# EFM32JG1B200F128GM32 register map
File version: 4.2.0
Registers are 32-bit, read-write, reset 0x0 unless marked. A register's access mark holds for its fields unless they carry their own. Offsets are from the block's base; [hi:lo] are bit positions; {n}, {i} and the like mark numbered series; 'fields as' and 'values as' point back to an identical list.

## CMU
Base 0x400E4000
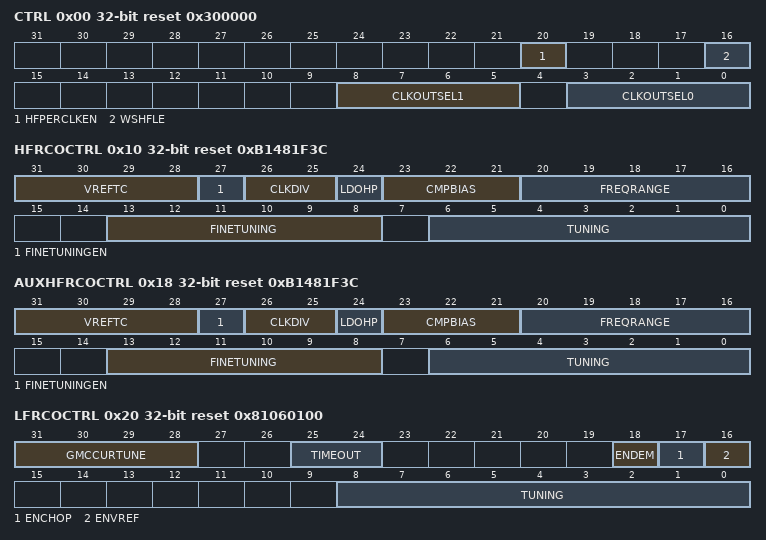
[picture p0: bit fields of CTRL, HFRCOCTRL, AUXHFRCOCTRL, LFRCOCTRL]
0x00 CTRL reset 0x300000 — CMU Control Register
  [20] HFPERCLKEN — HFPERCLK Enable
  [16] WSHFLE — Wait State for High-Frequency LE Interface
  [8:5] CLKOUTSEL1 — Clock Output Select 1
    0=DISABLED; 1=ULFRCO (ULFRCO (directly from oscillator)); 2=LFRCO (LFRCO (directly from oscillator)); 3=LFXO (LFXO (directly from oscillator)); 6=HFXO (HFXO (directly from oscillator)); 7=HFEXPCLK; 9=ULFRCOQ (ULFRCO (qualified)); 10=LFRCOQ (LFRCO (qualified)); 11=LFXOQ (LFXO (qualified)); 12=HFRCOQ (HFRCO (qualified)); 13=AUXHFRCOQ (AUXHFRCO (qualified)); 14=HFXOQ (HFXO (qualified)); 15=HFSRCCLK
  [3:0] CLKOUTSEL0 — Clock Output Select 0
    values as CLKOUTSEL1
0x10 HFRCOCTRL reset 0xB1481F3C — HFRCO Control Register
  [31:28] VREFTC — HFRCO Temperature Coefficient Trim on Comparator Reference
  [27] FINETUNINGEN — Enable reference for fine tuning
  [26:25] CLKDIV — Locally divide HFRCO Clock Output
    0=DIV1 (Divide by 1.); 1=DIV2 (Divide by 2.); 2=DIV4 (Divide by 4.)
  [24] LDOHP — HFRCO LDO High Power Mode
  [23:21] CMPBIAS — HFRCO Comparator Bias Current
  [20:16] FREQRANGE — HFRCO Frequency Range
  [13:8] FINETUNING — HFRCO Fine Tuning Value
  [6:0] TUNING — HFRCO Tuning Value
0x18 AUXHFRCOCTRL reset 0xB1481F3C — AUXHFRCO Control Register
  [31:28] VREFTC — AUXHFRCO Temperature Coefficient Trim on Comparator Reference
  [27] FINETUNINGEN — Enable reference for fine tuning
  [26:25] CLKDIV — Locally divide AUXHFRCO Clock Output
    values as HFRCOCTRL.CLKDIV
  [24] LDOHP — AUXHFRCO LDO High Power Mode
  [23:21] CMPBIAS — AUXHFRCO Comparator Bias Current
  [20:16] FREQRANGE — AUXHFRCO Frequency Range
  [13:8] FINETUNING — AUXHFRCO Fine Tuning Value
  [6:0] TUNING — AUXHFRCO Tuning Value
0x20 LFRCOCTRL reset 0x81060100 — LFRCO Control Register
  [31:28] GMCCURTUNE — Tuning of gmc current
  [25:24] TIMEOUT — LFRCO Timeout
    0=2CYCLES (Timeout period of 2 cycles); 1=16CYCLES (Timeout period of 16 cycles); 2=32CYCLES (Timeout period of 32 cycles)
  [18] ENDEM — Enable dynamic element matching
  [17] ENCHOP — Enable comparator chopping
  [16] ENVREF — Enable duty cycling of vref
  [8:0] TUNING — LFRCO Tuning Value
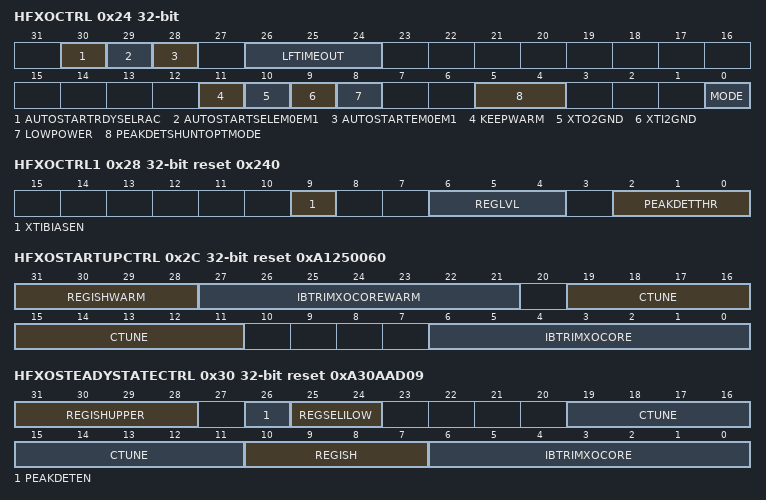
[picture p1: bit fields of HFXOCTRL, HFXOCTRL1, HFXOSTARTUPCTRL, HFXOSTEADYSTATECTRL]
0x24 HFXOCTRL — HFXO Control Register
  [30] AUTOSTARTRDYSELRAC — Automatically start HFXO on RAC wake-up and select it upon HFXO Ready
  [29] AUTOSTARTSELEM0EM1 — Automatically start and select of HFXO upon EM0/EM1 entry from EM2/EM3
  [28] AUTOSTARTEM0EM1 — Automatically start of HFXO upon EM0/EM1 entry from EM2/EM3
  [26:24] LFTIMEOUT — HFXO Low Frequency Timeout
    0=0CYCLES (Timeout period of 0 cycles (disabled)); 1=2CYCLES (Timeout period of 2 cycles); 2=4CYCLES (Timeout period of 4 cycles); 3=16CYCLES (Timeout period of 16 cycles); 4=32CYCLES (Timeout period of 32 cycles); 5=64CYCLES (Timeout period of 64 cycles); 6=1KCYCLES (Timeout period of 1024 cycles); 7=4KCYCLES (Timeout period of 4096 cycles)
  [11] KEEPWARM — Keep HFXO warm when turning off HFXO.
  [10] XTO2GND — Clamp HFXTAL_P pin to ground when HFXO oscillator is off and KEEPWARM=0.
  [9] XTI2GND — Clamp HFXTAL_N pin to ground when HFXO oscillator is off and KEEPWARM=0.
  [8] LOWPOWER — Low power mode control. PSR performance is reduced to enable low current consumption.
  [5:4] PEAKDETSHUNTOPTMODE — HFXO Automatic Peak Detection and shunt current optimization mode
    0=AUTOCMD (Automatic control of HFXO peak detection and shunt optimization sequences. CMU_CMD HFXOPEAKDETSTART and HFXOSHUNTOPTSTART can also be used.); 1=CMD (CMU_CMD HFXOPEAKDETSTART and HFXOSHUNTOPTSTART can be used to trigger peak detection and shunt optimization sequences.); 2=MANUAL (CMU_HFXOSTEADYSTATECTRL IBTRIMXOCORE, REGISH, REGSELILOW, and PEAKDETEN are under full software control and are allowed to be changed once HFXO is ready.)
  [0] MODE — HFXO Mode
0x28 HFXOCTRL1 reset 0x240 — HFXO Control 1
  [9] XTIBIASEN — Reserved for internal use. Do not change.
  [6:4] REGLVL — Reserved for internal use. Do not change.
  [2:0] PEAKDETTHR — Sets the Peak Detector amplitude detection threshold levels
0x2C HFXOSTARTUPCTRL reset 0xA1250060 — HFXO Startup Control
  [31:28] REGISHWARM — Sets the regulator output current level (shunt regulator). Ish = 120uA + REGISHWARM x 120uA
  [27:21] IBTRIMXOCOREWARM — Sets the oscillator core bias current. Current (uA) = IBTRIMXOCOREWARM x 40uA. Bits 6 and 5 may only be high in the crystal oscillator startup phase
  [19:11] CTUNE — Sets oscillator tuning capacitance. Capacitance on HFXTAL_N and HFXTAL_P (pF) = Ctune = Cpar + CTUNE<8:0> x 40fF. Max Ctune 25pF (CLmax ~12.5pF). CL(DNLmax)=50fF ~ 0.6ppm (12.5ppm/pF)
  [6:0] IBTRIMXOCORE — Sets the startup oscillator core bias current. Current (uA) = IBTRIMXOCORE x 40uA. Bits 6 and 5 may only be high in the crystal oscillator startup phase
0x30 HFXOSTEADYSTATECTRL reset 0xA30AAD09 — HFXO Steady State control
  [31:28] REGISHUPPER — Set regulator output current level (shunt regulator). Ish = 120uA + REGISHUPPER x 120uA
  [26] PEAKDETEN — Enables oscillator peak detectors
  [25:24] REGSELILOW — Controls regulator minimum shunt current detection relative to nominal
  [19:11] CTUNE — Sets oscillator tuning capacitance. Capacitance on HFXTAL_N and HFXTAL_P (pF) = Ctune = Cpar + CTUNE<8:0> x 40fF. Max Ctune 25pF (CLmax ~12.5pF). CL(DNLmax)=50fF ~ 0.6ppm (12.5ppm/pF)
  [10:7] REGISH — Sets the steady state regulator output current level (shunt regulator). Ish = 120uA + REGISH x 120uA
  [6:0] IBTRIMXOCORE — Sets the steady state oscillator core bias current. Current (uA) = IBTRIMXOCORE x 40uA. Bits 6 and 5 may only be high in the crystal oscillator startup phase
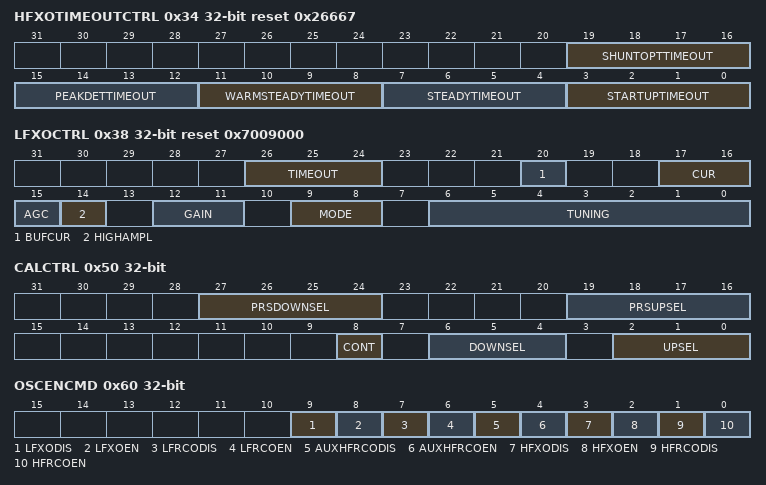
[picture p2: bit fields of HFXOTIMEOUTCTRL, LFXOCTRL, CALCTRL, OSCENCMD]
0x34 HFXOTIMEOUTCTRL reset 0x26667 — HFXO Timeout Control
  [all] fields
    0=2CYCLES (Timeout period of 2 cycles); 1=4CYCLES (Timeout period of 4 cycles); 2=16CYCLES (Timeout period of 16 cycles); 3=32CYCLES (Timeout period of 32 cycles); 4=256CYCLES (Timeout period of 256 cycles); 5=1KCYCLES (Timeout period of 1024 cycles); 6=2KCYCLES (Timeout period of 2048 cycles); 7=4KCYCLES (Timeout period of 4096 cycles); 8=8KCYCLES (Timeout period of 8192 cycles); 9=16KCYCLES (Timeout period of 16384 cycles); 10=32KCYCLES (Timeout period of 32768 cycles)
  [19:16] SHUNTOPTTIMEOUT — Wait duration in HFXO shunt current optimization wait state
  [15:12] PEAKDETTIMEOUT — Wait duration in HFXO peak detection wait state
  [11:8] WARMSTEADYTIMEOUT — Wait duration in HFXO warm startup steady wait state
  [7:4] STEADYTIMEOUT — Wait duration in HFXO startup steady wait state
  [3:0] STARTUPTIMEOUT — Wait duration in HFXO startup enable wait state
0x38 LFXOCTRL reset 0x7009000 — LFXO Control Register
  [26:24] TIMEOUT — LFXO Timeout
    0=2CYCLES (Timeout period of 2 cycles); 1=256CYCLES (Timeout period of 256 cycles); 2=1KCYCLES (Timeout period of 1024 cycles); 3=2KCYCLES (Timeout period of 2048 cycles); 4=4KCYCLES (Timeout period of 4096 cycles); 5=8KCYCLES (Timeout period of 8192 cycles); 6=16KCYCLES (Timeout period of 16384 cycles); 7=32KCYCLES (Timeout period of 32768 cycles)
  [20] BUFCUR — LFXO Buffer Bias Current
  [17:16] CUR — LFXO Current Trim
  [15] AGC — LFXO AGC Enable
  [14] HIGHAMPL — LFXO High XTAL Oscillation Amplitude Enable
  [12:11] GAIN — LFXO Startup Gain
  [9:8] MODE — LFXO Mode
    0=XTAL (32768 Hz crystal oscillator); 1=BUFEXTCLK (An AC coupled buffer is coupled in series with LFXTAL_N pin, suitable for external sinus wave (32768 Hz).); 2=DIGEXTCLK (Digital external clock on LFXTAL_N pin. Oscillator is effectively bypassed.)
  [6:0] TUNING — LFXO Internal Capacitor Array Tuning Value
0x50 CALCTRL — Calibration Control Register
  [27:24] PRSDOWNSEL — PRS Select for PRS Input when selected in DOWNSEL
    {v}=PRSCH{v} (PRS Channel {v} selected as input) (v=0..11)
  [19:16] PRSUPSEL — PRS Select for PRS Input when selected in UPSEL
    {v}=PRSCH{v} (PRS Channel {v} selected as input) (v=0..11)
  [8] CONT — Continuous Calibration
  [6:4] DOWNSEL — Calibration Down-counter Select
    0=HFCLK (Select HFCLK for down-counter); 1=HFXO (Select HFXO for down-counter); 2=LFXO (Select LFXO for down-counter); 3=HFRCO (Select HFRCO for down-counter); 4=LFRCO (Select LFRCO for down-counter); 5=AUXHFRCO (Select AUXHFRCO for down-counter); 6=PRS (Select PRS input selected by PRSDOWNSEL as down-counter)
  [2:0] UPSEL — Calibration Up-counter Select
    0=HFXO (Select HFXO as up-counter); 1=LFXO (Select LFXO as up-counter); 2=HFRCO (Select HFRCO as up-counter); 3=LFRCO (Select LFRCO as up-counter); 4=AUXHFRCO (Select AUXHFRCO as up-counter); 5=PRS (Select PRS input selected by PRSUPSEL as up-counter)
0x54 CALCNT — Calibration Counter Register
  [19:0] CALCNT — Calibration Counter
0x60 OSCENCMD wo — Oscillator Enable/Disable Command Register
  [9] LFXODIS — LFXO Disable
  [8] LFXOEN — LFXO Enable
  [7] LFRCODIS — LFRCO Disable
  [6] LFRCOEN — LFRCO Enable
  [5] AUXHFRCODIS — AUXHFRCO Disable
  [4] AUXHFRCOEN — AUXHFRCO Enable
  [3] HFXODIS — HFXO Disable
  [2] HFXOEN — HFXO Enable
  [1] HFRCODIS — HFRCO Disable
  [0] HFRCOEN — HFRCO Enable
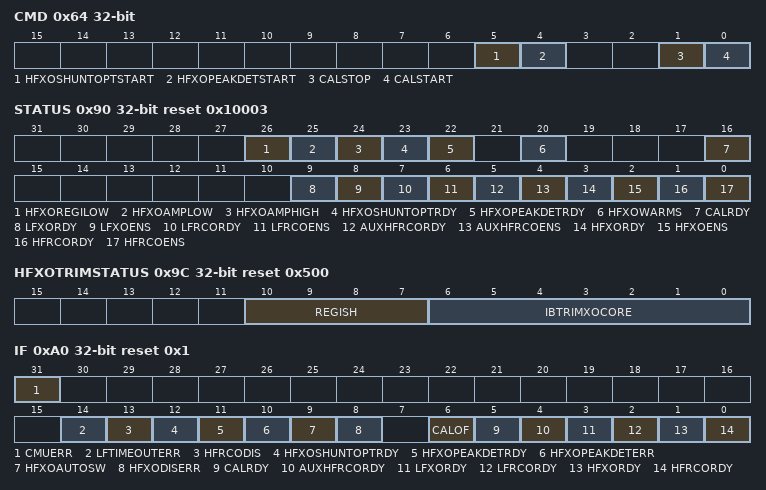
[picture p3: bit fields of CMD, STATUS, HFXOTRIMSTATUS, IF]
0x64 CMD wo — Command Register
  [5] HFXOSHUNTOPTSTART — HFXO Shunt Current Optimization Start
  [4] HFXOPEAKDETSTART — HFXO Peak Detection Start
  [1] CALSTOP — Calibration Stop
  [0] CALSTART — Calibration Start
0x70 DBGCLKSEL — Debug Trace Clock Select
  [0] DBG — Debug Trace Clock
    0=AUXHFRCO (AUXHFRCO is the debug trace clock); 1=HFCLK (HFCLK is the debug trace clock)
0x74 HFCLKSEL wo — High Frequency Clock Select Command Register
  [2:0] HF — HFCLK Select
    1=HFRCO (Select HFRCO as HFCLK); 2=HFXO (Select HFXO as HFCLK); 3=LFRCO (Select LFRCO as HFCLK); 4=LFXO (Select LFXO as HFCLK)
0x80 LFACLKSEL — Low Frequency A Clock Select Register
  [2:0] LFA — Clock Select for LFA
    0=DISABLED (LFACLK is disabled); 1=LFRCO (LFRCO selected as LFACLK); 2=LFXO (LFXO selected as LFACLK); 4=ULFRCO (ULFRCO selected as LFACLK)
0x84 LFBCLKSEL — Low Frequency B Clock Select Register
  [2:0] LFB — Clock Select for LFB
    0=DISABLED (LFBCLK is disabled); 1=LFRCO (LFRCO selected as LFBCLK); 2=LFXO (LFXO selected as LFBCLK); 3=HFCLKLE (HFCLK divided by two/four is selected as LFBCLK); 4=ULFRCO (ULFRCO selected as LFBCLK)
0x88 LFECLKSEL — Low Frequency E Clock Select Register
  [2:0] LFE — Clock Select for LFE
    0=DISABLED (LFECLK is disabled); 1=LFRCO (LFRCO selected as LFECLK); 2=LFXO (LFXO selected as LFECLK); 4=ULFRCO (ULFRCO selected as LFECLK)
0x90 STATUS ro reset 0x10003
  [26] HFXOREGILOW — HFXO regulator shunt current too low
  [25] HFXOAMPLOW — HFXO amplitude tuning value too low
  [24] HFXOAMPHIGH — HFXO oscillation amplitude is too high
  [23] HFXOSHUNTOPTRDY — HFXO Shunt Current Optimization ready
  [22] HFXOPEAKDETRDY — HFXO Peak Detection Ready
  [20] HFXOWARMS — HFXO Warm Status
  [16] CALRDY — Calibration Ready
  [9] LFXORDY — LFXO Ready
  [8] LFXOENS — LFXO Enable Status
  [7] LFRCORDY — LFRCO Ready
  [6] LFRCOENS — LFRCO Enable Status
  [5] AUXHFRCORDY — AUXHFRCO Ready
  [4] AUXHFRCOENS — AUXHFRCO Enable Status
  [3] HFXORDY — HFXO Ready
  [2] HFXOENS — HFXO Enable Status
  [1] HFRCORDY — HFRCO Ready
  [0] HFRCOENS — HFRCO Enable Status
0x94 HFCLKSTATUS ro reset 0x1
  [2:0] SELECTED — HFCLK Selected
    1=HFRCO (HFRCO is selected as HFCLK clock source); 2=HFXO (HFXO is selected as HFCLK clock source); 3=LFRCO (LFRCO is selected as HFCLK clock source); 4=LFXO (LFXO is selected as HFCLK clock source)
0x9C HFXOTRIMSTATUS ro reset 0x500
  [10:7] REGISH — Value of REGISH found by automatic HFXO shunt current optimization algorithm. Can be used as initial value for REGISH value in the CMU_HFXOSTEADYSTATECTRL register if HFXO is to be started again.
  [6:0] IBTRIMXOCORE — Value of IBTRIMXOCORE found by automatic HFXO peak detection algorithm. Can be used as initial value for IBTRIMXOCORE in the CMU_HFXOSTEADYSTATECTRL register if HFXO is to be started again.
0xA0 IF ro reset 0x1 — Interrupt Flag Register
  [31] CMUERR — CMU Error Interrupt Flag
  [14] LFTIMEOUTERR — Low Frequency Timeout Error Interrupt Flag
  [13] HFRCODIS — HFRCO Disable Interrupt Flag
  [12] HFXOSHUNTOPTRDY — HFXO Automatic Shunt Current Optimization Ready Interrupt Flag
  [11] HFXOPEAKDETRDY — HFXO Automatic Peak Detection Ready Interrupt Flag
  [10] HFXOPEAKDETERR — HFXO Automatic Peak Detection Error Interrupt Flag
  [9] HFXOAUTOSW — HFXO Automatic Switch Interrupt Flag
  [8] HFXODISERR — HFXO Disable Error Interrupt Flag
  [6] CALOF — Calibration Overflow Interrupt Flag
  [5] CALRDY — Calibration Ready Interrupt Flag
  [4] AUXHFRCORDY — AUXHFRCO Ready Interrupt Flag
  [3] LFXORDY — LFXO Ready Interrupt Flag
  [2] LFRCORDY — LFRCO Ready Interrupt Flag
  [1] HFXORDY — HFXO Ready Interrupt Flag
  [0] HFRCORDY — HFRCO Ready Interrupt Flag
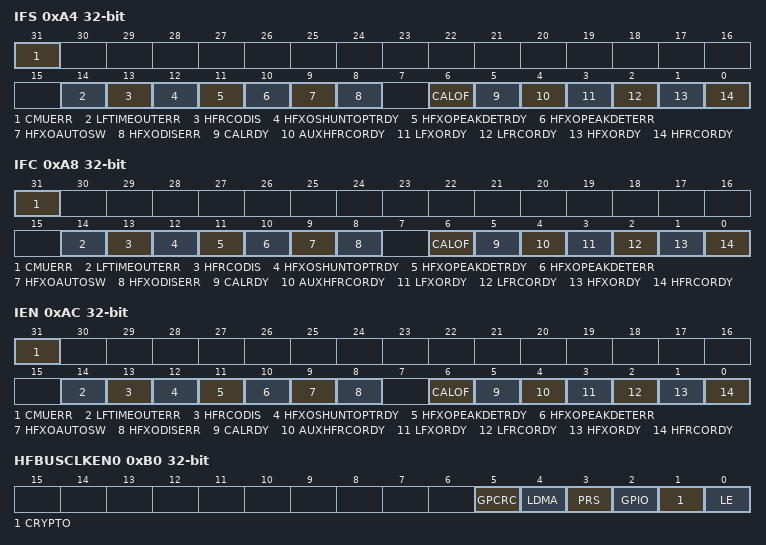
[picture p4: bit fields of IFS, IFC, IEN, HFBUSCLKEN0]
0xA4 IFS wo — Interrupt Flag Set Register
  [31] CMUERR — Set CMUERR Interrupt Flag
  [14] LFTIMEOUTERR — Set LFTIMEOUTERR Interrupt Flag
  [13] HFRCODIS — Set HFRCODIS Interrupt Flag
  [12] HFXOSHUNTOPTRDY — Set HFXOSHUNTOPTRDY Interrupt Flag
  [11] HFXOPEAKDETRDY — Set HFXOPEAKDETRDY Interrupt Flag
  [10] HFXOPEAKDETERR — Set HFXOPEAKDETERR Interrupt Flag
  [9] HFXOAUTOSW — Set HFXOAUTOSW Interrupt Flag
  [8] HFXODISERR — Set HFXODISERR Interrupt Flag
  [6] CALOF — Set CALOF Interrupt Flag
  [5] CALRDY — Set CALRDY Interrupt Flag
  [4] AUXHFRCORDY — Set AUXHFRCORDY Interrupt Flag
  [3] LFXORDY — Set LFXORDY Interrupt Flag
  [2] LFRCORDY — Set LFRCORDY Interrupt Flag
  [1] HFXORDY — Set HFXORDY Interrupt Flag
  [0] HFRCORDY — Set HFRCORDY Interrupt Flag
0xA8 IFC wo — Interrupt Flag Clear Register
  [31] CMUERR — Clear CMUERR Interrupt Flag
  [14] LFTIMEOUTERR — Clear LFTIMEOUTERR Interrupt Flag
  [13] HFRCODIS — Clear HFRCODIS Interrupt Flag
  [12] HFXOSHUNTOPTRDY — Clear HFXOSHUNTOPTRDY Interrupt Flag
  [11] HFXOPEAKDETRDY — Clear HFXOPEAKDETRDY Interrupt Flag
  [10] HFXOPEAKDETERR — Clear HFXOPEAKDETERR Interrupt Flag
  [9] HFXOAUTOSW — Clear HFXOAUTOSW Interrupt Flag
  [8] HFXODISERR — Clear HFXODISERR Interrupt Flag
  [6] CALOF — Clear CALOF Interrupt Flag
  [5] CALRDY — Clear CALRDY Interrupt Flag
  [4] AUXHFRCORDY — Clear AUXHFRCORDY Interrupt Flag
  [3] LFXORDY — Clear LFXORDY Interrupt Flag
  [2] LFRCORDY — Clear LFRCORDY Interrupt Flag
  [1] HFXORDY — Clear HFXORDY Interrupt Flag
  [0] HFRCORDY — Clear HFRCORDY Interrupt Flag
0xAC IEN — Interrupt Enable Register
  [31] CMUERR — CMUERR Interrupt Enable
  [14] LFTIMEOUTERR — LFTIMEOUTERR Interrupt Enable
  [13] HFRCODIS — HFRCODIS Interrupt Enable
  [12] HFXOSHUNTOPTRDY — HFXOSHUNTOPTRDY Interrupt Enable
  [11] HFXOPEAKDETRDY — HFXOPEAKDETRDY Interrupt Enable
  [10] HFXOPEAKDETERR — HFXOPEAKDETERR Interrupt Enable
  [9] HFXOAUTOSW — HFXOAUTOSW Interrupt Enable
  [8] HFXODISERR — HFXODISERR Interrupt Enable
  [6] CALOF — CALOF Interrupt Enable
  [5] CALRDY — CALRDY Interrupt Enable
  [4] AUXHFRCORDY — AUXHFRCORDY Interrupt Enable
  [3] LFXORDY — LFXORDY Interrupt Enable
  [2] LFRCORDY — LFRCORDY Interrupt Enable
  [1] HFXORDY — HFXORDY Interrupt Enable
  [0] HFRCORDY — HFRCORDY Interrupt Enable
0xB0 HFBUSCLKEN0 — High Frequency Bus Clock Enable Register 0
  [5] GPCRC — General Purpose CRC Clock Enable
  [4] LDMA — Linked Direct Memory Access Controller Clock Enable
  [3] PRS — Peripheral Reflex System Clock Enable
  [2] GPIO — General purpose Input/Output Clock Enable
  [1] CRYPTO — Advanced Encryption Standard Accelerator Clock Enable
  [0] LE — Low Energy Peripheral Interface Clock Enable
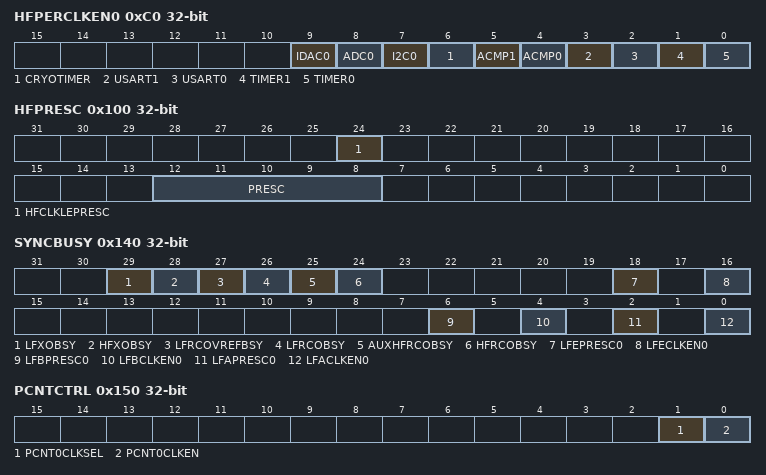
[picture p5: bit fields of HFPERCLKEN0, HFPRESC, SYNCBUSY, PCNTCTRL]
0xC0 HFPERCLKEN0 — High Frequency Peripheral Clock Enable Register 0
  [9] IDAC0 — Current Digital to Analog Converter 0 Clock Enable
  [8] ADC0 — Analog to Digital Converter 0 Clock Enable
  [7] I2C0 — I2C 0 Clock Enable
  [6] CRYOTIMER — CryoTimer Clock Enable
  [5] ACMP1 — Analog Comparator 1 Clock Enable
  [4] ACMP0 — Analog Comparator 0 Clock Enable
  [3] USART1 — Universal Synchronous/Asynchronous Receiver/Transmitter 1 Clock Enable
  [2] USART0 — Universal Synchronous/Asynchronous Receiver/Transmitter 0 Clock Enable
  [1] TIMER1 — Timer 1 Clock Enable
  [0] TIMER0 — Timer 0 Clock Enable
0xE0 LFACLKEN0 — Low Frequency A Clock Enable Register 0 (Async Reg)
  [0] LETIMER0 — Low Energy Timer 0 Clock Enable
0xE8 LFBCLKEN0 — Low Frequency B Clock Enable Register 0 (Async Reg)
  [0] LEUART0 — Low Energy UART 0 Clock Enable
0xF0 LFECLKEN0 — Low Frequency E Clock Enable Register 0 (Async Reg)
  [0] RTCC — Real-Time Counter and Calendar Clock Enable
0x100 HFPRESC — High Frequency Clock Prescaler Register
  [24] HFCLKLEPRESC — HFCLKLE prescaler
    0=DIV2 (HFCLKLE is HFBUSCLKLE divided by 2.); 1=DIV4 (HFCLKLE is HFBUSCLKLE divided by 4.)
  [12:8] PRESC — HFCLK Prescaler
    0=NODIVISION
0x108 HFCOREPRESC — High Frequency Core Clock Prescaler Register
  [16:8] PRESC — HFCORECLK Prescaler
    0=NODIVISION
0x10C HFPERPRESC — High Frequency Peripheral Clock Prescaler Register
  [16:8] PRESC — HFPERCLK Prescaler
    0=NODIVISION
0x114 HFEXPPRESC — High Frequency Export Clock Prescaler Register
  [12:8] PRESC — HFEXPCLK Prescaler
    0=NODIVISION
0x120 LFAPRESC0 — Low Frequency A Prescaler Register 0 (Async Reg)
  [3:0] LETIMER0 — Low Energy Timer 0 Prescaler
    0=DIV1 (LFACLKLETIMER0 = LFACLK); 1=DIV2 (LFACLKLETIMER0 = LFACLK/2); 2=DIV4 (LFACLKLETIMER0 = LFACLK/4); 3=DIV8 (LFACLKLETIMER0 = LFACLK/8); 4=DIV16 (LFACLKLETIMER0 = LFACLK/16); 5=DIV32 (LFACLKLETIMER0 = LFACLK/32); 6=DIV64 (LFACLKLETIMER0 = LFACLK/64); 7=DIV128 (LFACLKLETIMER0 = LFACLK/128); 8=DIV256 (LFACLKLETIMER0 = LFACLK/256); 9=DIV512 (LFACLKLETIMER0 = LFACLK/512); 10=DIV1024 (LFACLKLETIMER0 = LFACLK/1024); 11=DIV2048 (LFACLKLETIMER0 = LFACLK/2048); 12=DIV4096 (LFACLKLETIMER0 = LFACLK/4096); 13=DIV8192 (LFACLKLETIMER0 = LFACLK/8192); 14=DIV16384 (LFACLKLETIMER0 = LFACLK/16384); 15=DIV32768 (LFACLKLETIMER0 = LFACLK/32768)
0x128 LFBPRESC0 — Low Frequency B Prescaler Register 0 (Async Reg)
  [1:0] LEUART0 — Low Energy UART 0 Prescaler
    0=DIV1 (LFBCLKLEUART0 = LFBCLK); 1=DIV2 (LFBCLKLEUART0 = LFBCLK/2); 2=DIV4 (LFBCLKLEUART0 = LFBCLK/4); 3=DIV8 (LFBCLKLEUART0 = LFBCLK/8)
0x130 LFEPRESC0 — Low Frequency E Prescaler Register 0 (Async Reg)
  [3:0] RTCC ro — Real-Time Counter and Calendar Prescaler
    0=DIV1 (LFECLKRTCC = LFECLK)
0x140 SYNCBUSY ro — Synchronization Busy Register
  [29] LFXOBSY — LFXO Busy
  [28] HFXOBSY — HFXO Busy
  [27] LFRCOVREFBSY — LFRCO VREF Busy
  [26] LFRCOBSY — LFRCO Busy
  [25] AUXHFRCOBSY — AUXHFRCO Busy
  [24] HFRCOBSY — HFRCO Busy
  [18] LFEPRESC0 — Low Frequency E Prescaler 0 Busy
  [16] LFECLKEN0 — Low Frequency E Clock Enable 0 Busy
  [6] LFBPRESC0 — Low Frequency B Prescaler 0 Busy
  [4] LFBCLKEN0 — Low Frequency B Clock Enable 0 Busy
  [2] LFAPRESC0 — Low Frequency A Prescaler 0 Busy
  [0] LFACLKEN0 — Low Frequency A Clock Enable 0 Busy
0x144 FREEZE
  [0] REGFREEZE — Register Update Freeze
0x150 PCNTCTRL — PCNT Control Register
  [1] PCNT0CLKSEL — PCNT0 Clock Select
  [0] PCNT0CLKEN — PCNT0 Clock Enable
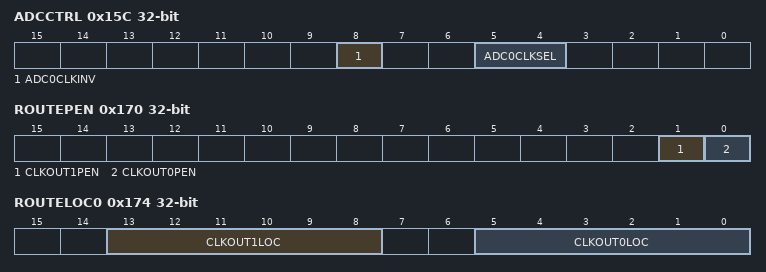
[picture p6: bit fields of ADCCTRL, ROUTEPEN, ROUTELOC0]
0x15C ADCCTRL — ADC Control Register
  [8] ADC0CLKINV — Invert clock selected by ADC0CLKSEL
  [5:4] ADC0CLKSEL — ADC0 Clock Select
    0=DISABLED (ADC0 is not clocked); 1=AUXHFRCO (AUXHFRCO is clocking ADC0); 2=HFXO (HFXO is clocking ADC0); 3=HFSRCCLK (HFSRCCLK is clocking ADC0)
0x170 ROUTEPEN — I/O Routing Pin Enable Register
  [1] CLKOUT1PEN — CLKOUT1 Pin Enable
  [0] CLKOUT0PEN — CLKOUT0 Pin Enable
0x174 ROUTELOC0 — I/O Routing Location Register
  [13:8] CLKOUT1LOC — I/O Location
    {v}=LOC{v} (Location {v}) (v=0..7)
  [5:0] CLKOUT0LOC — I/O Location
    {v}=LOC{v} (Location {v}) (v=0..7)
0x180 LOCK — Configuration Lock Register
  [15:0] LOCKKEY — Configuration Lock Key
    0=UNLOCKED; 1=LOCKED
